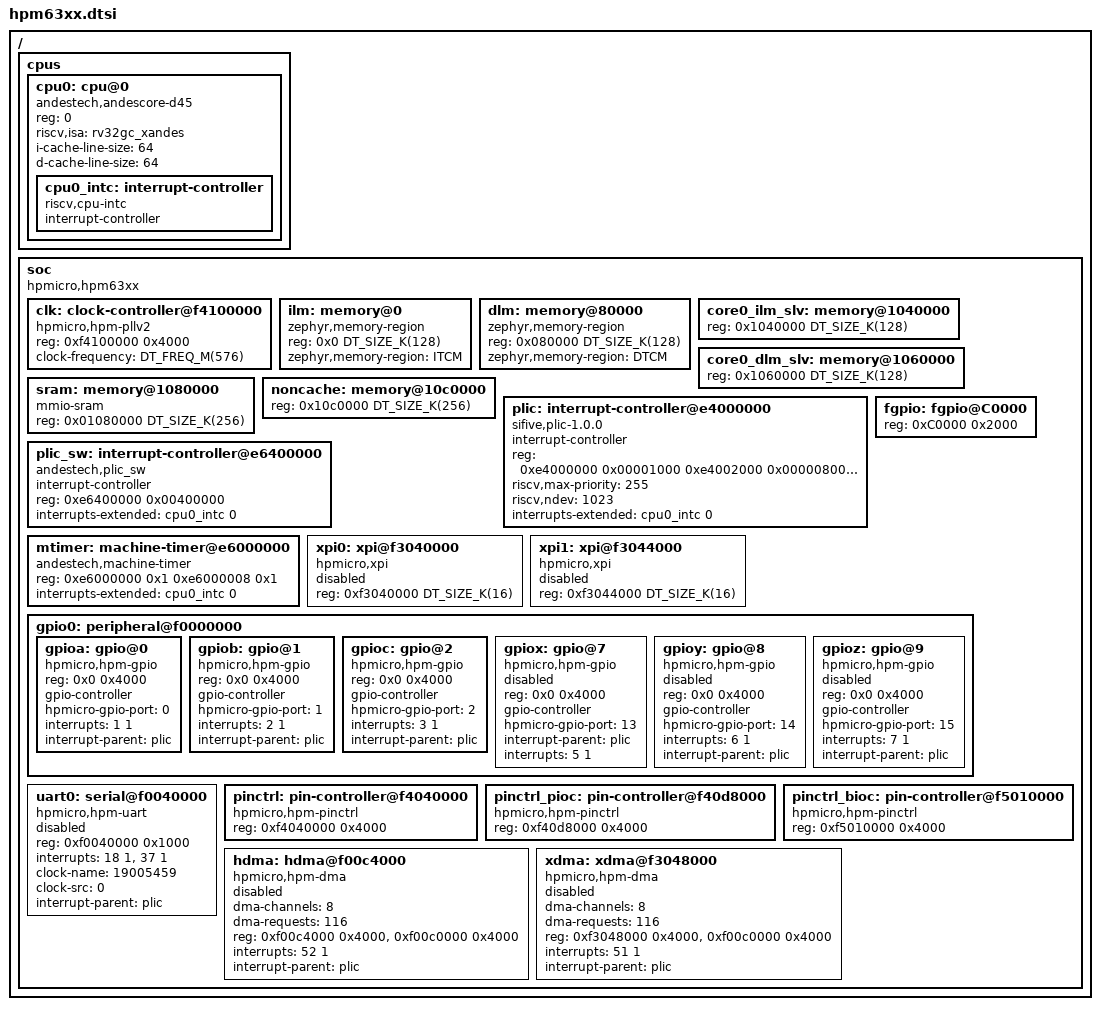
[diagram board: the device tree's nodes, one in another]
/*
 * Copyright 2024 HPMicro
 * SPDX-License-Identifier: Apache-2.0
 */

/dts-v1/;
#include <zephyr/dt-bindings/gpio/gpio.h>
#include <dt-bindings/clock/hpmicro-clocks.h>
#include <mem.h>
#include <freq.h>

/ {
	#address-cells = <1>;
	#size-cells = <1>;

	cpus {
		#address-cells = <1>;
		#size-cells = <0>;
		cpu0: cpu@0 {
			compatible = "andestech,andescore-d45", "riscv"; /* riscv custom */
			reg = <0>;
			status = "okay";
			riscv,isa = "rv32gc_xandes";
			i-cache-line-size = <64>;
			d-cache-line-size = <64>;

			cpu0_intc: interrupt-controller {
				compatible = "riscv,cpu-intc";
				#address-cells = <0>;
				#interrupt-cells = <1>;
				interrupt-controller;
			};
		};
	};

	soc {
		#address-cells = <1>;
		#size-cells = <1>;
		compatible = "hpmicro,hpm63xx";
		ranges;

		clk: clock-controller@f4100000 {
			compatible = "hpmicro,hpm-pllv2";
			reg = <0xf4100000 0x4000>;
			clock-frequency = <DT_FREQ_M(576)>;
			reg-names = "clk";
			status = "okay";
		};

		ilm: memory@0 {
			compatible = "zephyr,memory-region";
			reg = <0x0 DT_SIZE_K(128)>;
			zephyr,memory-region = "ITCM";
		};

		dlm: memory@80000 {
			compatible = "zephyr,memory-region";
			reg = <0x080000 DT_SIZE_K(128)>;
			zephyr,memory-region = "DTCM";
		};

		core0_ilm_slv: memory@1040000 {
			reg = <0x1040000 DT_SIZE_K(128)>;
		};

		core0_dlm_slv: memory@1060000 {
			reg = <0x1060000 DT_SIZE_K(128)>;
		};

		sram: memory@1080000 {
			compatible = "mmio-sram";
			reg = <0x01080000 DT_SIZE_K(256)>;
		};

		noncache: memory@10c0000 {
			reg = <0x10c0000 DT_SIZE_K(256)>;
		};

		plic: interrupt-controller@e4000000 {
			compatible = "sifive,plic-1.0.0";
			#address-cells = <1>;
			#interrupt-cells = <2>;
			interrupt-controller;
			reg = <	0xe4000000 0x00001000
				0xe4002000 0x00000800
				0xe4200000 0x00010000 >;
			reg-names = "prio", "irq_en", "reg";
			riscv,max-priority = <255>;
			riscv,ndev = <1023>;
			interrupts-extended = <&cpu0_intc 0>;
		};

		plic_sw: interrupt-controller@e6400000 {
			compatible = "andestech,plic_sw";
			#address-cells = <1>;
			#interrupt-cells = <2>;
			interrupt-controller;
			reg = <0xe6400000 0x00400000>;
			interrupts-extended = <&cpu0_intc 0>;
		};

		mtimer: machine-timer@e6000000 {
			compatible = "andestech,machine-timer";
			reg = <0xe6000000 0x1
			0xe6000008 0x1>;
			interrupts-extended = <&cpu0_intc 0>;
		};

		fgpio: fgpio@C0000 {
			reg = <0xC0000 0x2000>;
		};

		xpi0: xpi@f3040000 {
			compatible = "hpmicro,xpi";
			reg = <0xf3040000 DT_SIZE_K(16)>;
			#address-cells = <1>;
			#size-cells = <1>;
			status = "disabled";
		};

		xpi1: xpi@f3044000 {
			compatible = "hpmicro,xpi";
			reg = <0xf3044000 DT_SIZE_K(16)>;
			status = "disabled";
		};

		gpio0: peripheral@f0000000 {
			#address-cells = <1>;
			#size-cells = <1>;
			ranges = <0x0 0xf0000000 0x4000>;
		};

		uart0: serial@f0040000 {
			compatible = "hpmicro,hpm-uart";
			reg = <0xf0040000 0x1000>;
			interrupts = <18 1>, <37 1>;
			interrupt-names = "uart", "idletimer";
			clock-name = <19005459>;
			clock-src = <0>;
			interrupt-parent = <&plic>;
			status = "disabled";
		};

		pinctrl: pin-controller@f4040000 {
			compatible = "hpmicro,hpm-pinctrl";
			reg = <0xf4040000 0x4000>;
			status = "okay";
		};

		pinctrl_pioc: pin-controller@f40d8000 {
			compatible = "hpmicro,hpm-pinctrl";
			reg = <0xf40d8000 0x4000>;
			status = "okay";
		};

		pinctrl_bioc: pin-controller@f5010000 {
			compatible = "hpmicro,hpm-pinctrl";
			reg = <0xf5010000 0x4000>;
			status = "okay";
		};

		hdma: hdma@f00c4000 {
			#dma-cells = <2>;
			compatible = "hpmicro,hpm-dma";
			dma-channels = <8>;
			dma-requests = <116>;
			reg = <0xf00c4000 0x4000>,
				<0xf00c0000 0x4000>; /* DMAMUX base */
			interrupts = <52 1>;
			interrupt-parent = <&plic>;
			status = "disabled";
		};

		xdma: xdma@f3048000 {
			#dma-cells = <2>;
			compatible = "hpmicro,hpm-dma";
			dma-channels = <8>;
			dma-requests = <116>;
			reg = <0xf3048000 0x4000>,
				<0xf00c0000 0x4000>; /* DMAMUX base */
			interrupts = <51 1>;
			interrupt-parent = <&plic>;
			status = "disabled";
		};
	};
};

&gpio0 {
	gpioa: gpio@0 {
		compatible = "hpmicro,hpm-gpio";
		reg = <0x0 0x4000>;
		gpio-controller;
		#gpio-cells = <2>;
		hpmicro-gpio-port = <0>;
		interrupts = <1 1>;
		interrupt-parent = <&plic>;
	};

	gpiob: gpio@1 {
		compatible = "hpmicro,hpm-gpio";
		reg = <0x0 0x4000>;
		gpio-controller;
		#gpio-cells = <2>;
		hpmicro-gpio-port = <1>;
		interrupts = <2 1>;
		interrupt-parent = <&plic>;
	};

	gpioc: gpio@2 {
		compatible = "hpmicro,hpm-gpio";
		reg = <0x0 0x4000>;
		gpio-controller;
		#gpio-cells = <2>;
		hpmicro-gpio-port = <2>;
		interrupts = <3 1>;
		interrupt-parent = <&plic>;
	};

	gpiox: gpio@7 {
		compatible = "hpmicro,hpm-gpio";
		reg = <0x0 0x4000>;
		gpio-controller;
		#gpio-cells = <2>;
		hpmicro-gpio-port = <13>;
		interrupt-parent = <&plic>;
		interrupts = <5 1>;
		status = "disabled";
	};

	gpioy: gpio@8 {
		compatible = "hpmicro,hpm-gpio";
		reg = <0x0 0x4000>;
		gpio-controller;
		#gpio-cells = <2>;
		hpmicro-gpio-port = <14>;
		interrupts = <6 1>;
		interrupt-parent = <&plic>;
		status = "disabled";
	};

	gpioz: gpio@9 {
		compatible = "hpmicro,hpm-gpio";
		reg = <0x0 0x4000>;
		gpio-controller;
		#gpio-cells = <2>;
		hpmicro-gpio-port = <15>;
		interrupts = <7 1>;
		interrupt-parent = <&plic>;
		status = "disabled";
	};
};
